# ATSAM3A4C register map
Vendor: Atmel; File version: 0
CPU: CM3 r2p0, selectable endian, no MPU, no FPU, 0x4 interrupt priority bits, 0x0 interrupts
Registers are 32-bit, read-write, no defined reset value unless marked. A register's access mark holds for its fields unless they carry their own. Offsets are from the block's base; [hi:lo] are bit positions; {n}, {i} and the like mark numbered series; 'fields as' and 'values as' point back to an identical list.

## CAN0 — Controller Area Network 0
Base 0x400B4000; register names take the prefix CAN0_
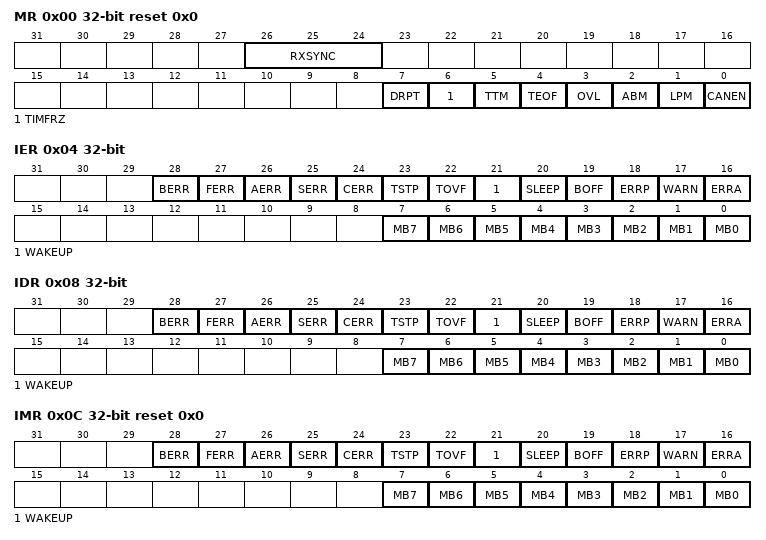
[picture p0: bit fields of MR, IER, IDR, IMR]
0x00 MR reset 0x0 — Mode Register
  [26:24] RXSYNC — Reception Synchronization Stage (not readable)
    0=DOUBLE_PP (Rx Signal with Double Synchro Stages (2 Positive Edges)); 1=DOUBLE_PN (Rx Signal with Double Synchro Stages (One Positive Edge and One Negative Edge)); 2=SINGLE_P (Rx Signal with Single Synchro Stage (Positive Edge)); 3=NONE (Rx Signal with No Synchro Stage)
  [7] DRPT — Disable Repeat
  [6] TIMFRZ — Enable Timer Freeze
  [5] TTM — Disable/Enable Time Triggered Mode
  [4] TEOF — Timestamp messages at each end of Frame
  [3] OVL — Disable/Enable Overload Frame
  [2] ABM — Disable/Enable Autobaud/Listen mode
  [1] LPM — Disable/Enable Low Power Mode
  [0] CANEN — CAN Controller Enable
0x04 IER wo — Interrupt Enable Register
  [28] BERR — Bit Error Interrupt Enable
  [27] FERR — Form Error Interrupt Enable
  [26] AERR — Acknowledgment Error Interrupt Enable
  [25] SERR — Stuffing Error Interrupt Enable
  [24] CERR — CRC Error Interrupt Enable
  [23] TSTP — TimeStamp Interrupt Enable
  [22] TOVF — Timer Overflow Interrupt Enable
  [21] WAKEUP — Wakeup Interrupt Enable
  [20] SLEEP — Sleep Interrupt Enable
  [19] BOFF — Bus Off Mode Interrupt Enable
  [18] ERRP — Error Passive Mode Interrupt Enable
  [17] WARN — Warning Limit Interrupt Enable
  [16] ERRA — Error Active Mode Interrupt Enable
  [n] MB{n} (n=0..7) — Mailbox {n} Interrupt Enable
0x08 IDR wo — Interrupt Disable Register
  [28] BERR — Bit Error Interrupt Disable
  [27] FERR — Form Error Interrupt Disable
  [26] AERR — Acknowledgment Error Interrupt Disable
  [25] SERR — Stuffing Error Interrupt Disable
  [24] CERR — CRC Error Interrupt Disable
  [23] TSTP — TimeStamp Interrupt Disable
  [22] TOVF — Timer Overflow Interrupt
  [21] WAKEUP — Wakeup Interrupt Disable
  [20] SLEEP — Sleep Interrupt Disable
  [19] BOFF — Bus Off Mode Interrupt Disable
  [18] ERRP — Error Passive Mode Interrupt Disable
  [17] WARN — Warning Limit Interrupt Disable
  [16] ERRA — Error Active Mode Interrupt Disable
  [n] MB{n} (n=0..7) — Mailbox {n} Interrupt Disable
0x0C IMR ro reset 0x0 — Interrupt Mask Register
  [28] BERR — Bit Error Interrupt Mask
  [27] FERR — Form Error Interrupt Mask
  [26] AERR — Acknowledgment Error Interrupt Mask
  [25] SERR — Stuffing Error Interrupt Mask
  [24] CERR — CRC Error Interrupt Mask
  [23] TSTP — Timestamp Interrupt Mask
  [22] TOVF — Timer Overflow Interrupt Mask
  [21] WAKEUP — Wakeup Interrupt Mask
  [20] SLEEP — Sleep Interrupt Mask
  [19] BOFF — Bus Off Mode Interrupt Mask
  [18] ERRP — Error Passive Mode Interrupt Mask
  [17] WARN — Warning Limit Interrupt Mask
  [16] ERRA — Error Active Mode Interrupt Mask
  [n] MB{n} (n=0..7) — Mailbox {n} Interrupt Mask
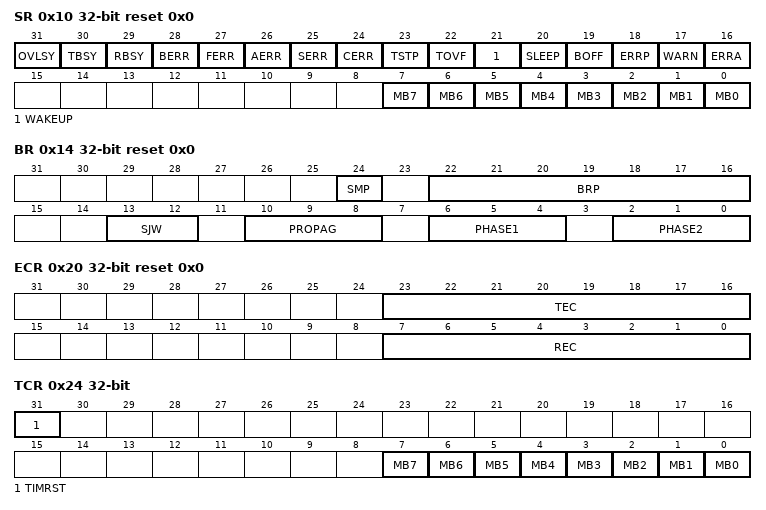
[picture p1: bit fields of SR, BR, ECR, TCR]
0x10 SR ro reset 0x0 — Status Register
  [31] OVLSY — Overload busy
  [30] TBSY — Transmitter busy
  [29] RBSY — Receiver busy
  [28] BERR — Bit Error
  [27] FERR — Form Error
  [26] AERR — Acknowledgment Error
  [25] SERR — Mailbox Stuffing Error
  [24] CERR — Mailbox CRC Error
  [23] TSTP
  [22] TOVF — Timer Overflow
  [21] WAKEUP — CAN controller is not in Low power Mode
  [20] SLEEP — CAN controller in Low power Mode
  [19] BOFF — Bus Off Mode
  [18] ERRP — Error Passive Mode
  [17] WARN — Warning Limit
  [16] ERRA — Error Active Mode
  [n] MB{n} (n=0..7) — Mailbox {n} Event
0x14 BR reset 0x0 — Baudrate Register
  [24] SMP — Sampling Mode
    0=ONCE (The incoming bit stream is sampled once at sample point.); 1=THREE (The incoming bit stream is sampled three times with a period of a MCK clock period, centered on sample point.)
  [22:16] BRP — Baudrate Prescaler.
  [13:12] SJW — Re-synchronization jump width
  [10:8] PROPAG — Programming time segment
  [6:4] PHASE1 — Phase 1 segment
  [2:0] PHASE2 — Phase 2 segment
0x18 TIM ro reset 0x0 — Timer Register
  [15:0] TIMER
0x1C TIMESTP ro reset 0x0 — Timestamp Register
  [15:0] MTIMESTAMP — Timestamp
0x20 ECR ro reset 0x0 — Error Counter Register
  [23:16] TEC — Transmit Error Counter
  [7:0] REC — Receive Error Counter
0x24 TCR wo — Transfer Command Register
  [31] TIMRST — Timer Reset
  [n] MB{n} (n=0..7) — Transfer Request for Mailbox {n}
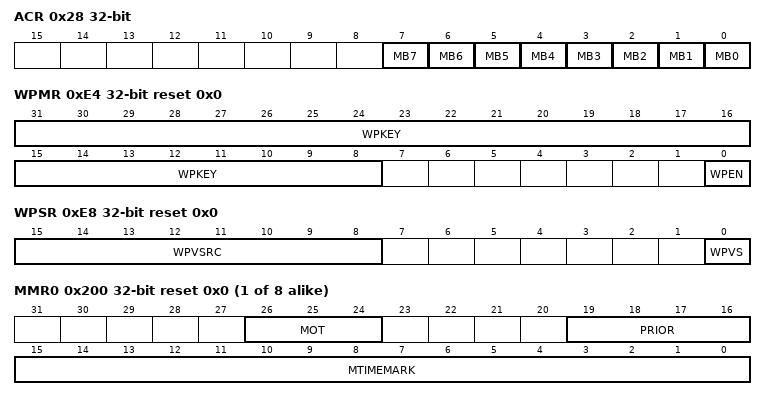
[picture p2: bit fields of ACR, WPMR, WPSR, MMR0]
0x28 ACR wo — Abort Command Register
  [n] MB{n} (n=0..7) — Abort Request for Mailbox {n}
0xE4 WPMR reset 0x0 — Write Protect Mode Register
  [31:8] WPKEY — SPI Write Protection Key Password
  [0] WPEN — Write Protection Enable
0xE8 WPSR ro reset 0x0 — Write Protect Status Register
  [15:8] WPVSRC — Write Protection Violation Source
  [0] WPVS — Write Protection Violation Status
{0x200+0x20*i} MMR{i} reset 0x0 (i=0..7) — Mailbox Mode Register (MB = {i})
  [26:24] MOT — Mailbox Object Type
    0=MB_DISABLED (Mailbox is disabled. This prevents receiving or transmitting any messages with this mailbox.); 1=MB_RX (Reception Mailbox. Mailbox is configured for reception. If a message is received while the mailbox data register is full, it is discarded.); 2=MB_RX_OVERWRITE (Reception mailbox with overwrite. Mailbox is configured for reception. If a message is received while the mailbox is full, it overwrites the previous message.); 3=MB_TX (Transmit mailbox. Mailbox is configured for transmission.); 4=MB_CONSUMER (Consumer Mailbox. Mailbox is configured in reception but behaves as a Transmit Mailbox, i.e., it sends a remote frame and waits for an answer.); 5=MB_PRODUCER (Producer Mailbox. Mailbox is configured in transmission but also behaves like a reception mailbox, i.e., it waits to receive a Remote Frame before sending its contents.)
  [19:16] PRIOR — Mailbox Priority
  [15:0] MTIMEMARK — Mailbox Timemark
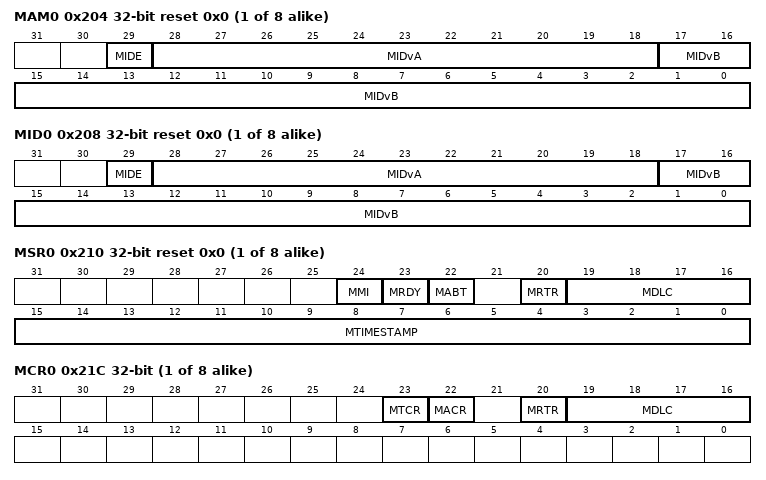
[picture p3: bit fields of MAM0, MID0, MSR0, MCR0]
{0x204+0x20*i} MAM{i} reset 0x0 (i=0..7) — Mailbox Acceptance Mask Register (MB = {i})
  [29] MIDE — Identifier Version
  [28:18] MIDvA — Identifier for standard frame mode
  [17:0] MIDvB — Complementary bits for identifier in extended frame mode
{0x208+0x20*i} MID{i} reset 0x0 (i=0..7) — Mailbox ID Register (MB = {i})
  fields as MAM0
{0x20C+0x20*i} MFID{i} ro reset 0x0 (i=0..7) — Mailbox Family ID Register (MB = {i})
  [28:0] MFID — Family ID
{0x210+0x20*i} MSR{i} ro reset 0x0 (i=0..7) — Mailbox Status Register (MB = {i})
  [24] MMI — Mailbox Message Ignored
  [23] MRDY — Mailbox Ready
  [22] MABT — Mailbox Message Abort
  [20] MRTR — Mailbox Remote Transmission Request
  [19:16] MDLC — Mailbox Data Length Code
  [15:0] MTIMESTAMP — Timer value
{0x214+0x20*i} MDL{i} reset 0x0 (i=0..7) — Mailbox Data Low Register (MB = {i})
  [31:0] MDL — Message Data Low Value
{0x218+0x20*i} MDH{i} reset 0x0 (i=0..7) — Mailbox Data High Register (MB = {i})
  [31:0] MDH — Message Data High Value
{0x21C+0x20*i} MCR{i} wo (i=0..7) — Mailbox Control Register (MB = {i})
  [23] MTCR — Mailbox Transfer Command
  [22] MACR — Abort Request for Mailbox x
  [20] MRTR — Mailbox Remote Transmission Request
  [19:16] MDLC — Mailbox Data Length Code

## CAN1 — Controller Area Network 1
Base 0x400B8000; register names take the prefix CAN1_
Registers as CAN0.
